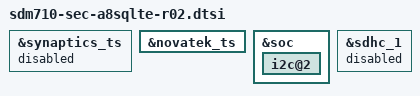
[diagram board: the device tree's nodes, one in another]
/* Copyright (c) 2016-2017, The Linux Foundation. All rights reserved.
 *
 * This program is free software; you can redistribute it and/or modify
 * it under the terms of the GNU General Public License version 2 and
 * only version 2 as published by the Free Software Foundation.
 *
 * This program is distributed in the hope that it will be useful,
 * but WITHOUT ANY WARRANTY; without even the implied warranty of
 * MERCHANTABILITY or FITNESS FOR A PARTICULAR PURPOSE.  See the
 * GNU General Public License for more details.
 */

#include "sdm710-sec-a8sqlte-r01.dtsi"

&synaptics_ts {
	status = "disabled";
};

&novatek_ts {
	status = "okay";
};

&soc {
	/* not use eMCP */
	/delete-property/ sdhc-msm-crypto;

	i2c@2 {
		status = "okay";
	};
};

&sdhc_1 {
	status = "disabled";
};
